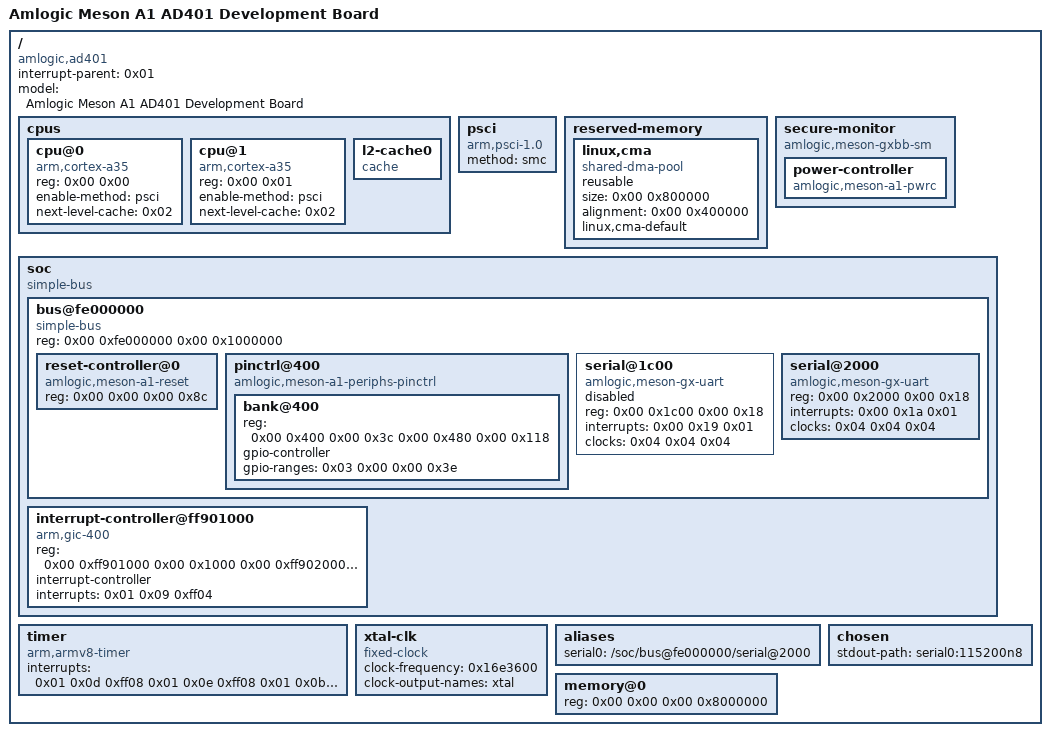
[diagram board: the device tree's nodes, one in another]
/dts-v1/;

/ {
	compatible = "amlogic,ad401\0amlogic,a1";
	interrupt-parent = <0x01>;
	#address-cells = <0x02>;
	#size-cells = <0x02>;
	model = "Amlogic Meson A1 AD401 Development Board";

	cpus {
		#address-cells = <0x02>;
		#size-cells = <0x00>;

		cpu@0 {
			device_type = "cpu";
			compatible = "arm,cortex-a35";
			reg = <0x00 0x00>;
			enable-method = "psci";
			next-level-cache = <0x02>;
			phandle = <0x05>;
		};

		cpu@1 {
			device_type = "cpu";
			compatible = "arm,cortex-a35";
			reg = <0x00 0x01>;
			enable-method = "psci";
			next-level-cache = <0x02>;
			phandle = <0x06>;
		};

		l2-cache0 {
			compatible = "cache";
			phandle = <0x02>;
		};
	};

	psci {
		compatible = "arm,psci-1.0";
		method = "smc";
	};

	reserved-memory {
		#address-cells = <0x02>;
		#size-cells = <0x02>;
		ranges;

		linux,cma {
			compatible = "shared-dma-pool";
			reusable;
			size = <0x00 0x800000>;
			alignment = <0x00 0x400000>;
			linux,cma-default;
		};
	};

	secure-monitor {
		compatible = "amlogic,meson-gxbb-sm";
		phandle = <0x07>;

		power-controller {
			compatible = "amlogic,meson-a1-pwrc";
			#power-domain-cells = <0x01>;
			status = "okay";
			phandle = <0x08>;
		};
	};

	soc {
		compatible = "simple-bus";
		#address-cells = <0x02>;
		#size-cells = <0x02>;
		ranges;

		bus@fe000000 {
			compatible = "simple-bus";
			reg = <0x00 0xfe000000 0x00 0x1000000>;
			#address-cells = <0x02>;
			#size-cells = <0x02>;
			ranges = <0x00 0x00 0x00 0xfe000000 0x00 0x1000000>;
			phandle = <0x09>;

			reset-controller@0 {
				compatible = "amlogic,meson-a1-reset";
				reg = <0x00 0x00 0x00 0x8c>;
				#reset-cells = <0x01>;
				phandle = <0x0a>;
			};

			pinctrl@400 {
				compatible = "amlogic,meson-a1-periphs-pinctrl";
				#address-cells = <0x02>;
				#size-cells = <0x02>;
				ranges;
				phandle = <0x03>;

				bank@400 {
					reg = <0x00 0x400 0x00 0x3c 0x00 0x480 0x00 0x118>;
					reg-names = "mux\0gpio";
					gpio-controller;
					#gpio-cells = <0x02>;
					gpio-ranges = <0x03 0x00 0x00 0x3e>;
					phandle = <0x0b>;
				};
			};

			serial@1c00 {
				compatible = "amlogic,meson-gx-uart\0amlogic,meson-ao-uart";
				reg = <0x00 0x1c00 0x00 0x18>;
				interrupts = <0x00 0x19 0x01>;
				clocks = <0x04 0x04 0x04>;
				clock-names = "xtal\0pclk\0baud";
				status = "disabled";
				phandle = <0x0c>;
			};

			serial@2000 {
				compatible = "amlogic,meson-gx-uart\0amlogic,meson-ao-uart";
				reg = <0x00 0x2000 0x00 0x18>;
				interrupts = <0x00 0x1a 0x01>;
				clocks = <0x04 0x04 0x04>;
				clock-names = "xtal\0pclk\0baud";
				status = "okay";
				phandle = <0x0d>;
			};
		};

		interrupt-controller@ff901000 {
			compatible = "arm,gic-400";
			reg = <0x00 0xff901000 0x00 0x1000 0x00 0xff902000 0x00 0x2000 0x00 0xff904000 0x00 0x2000 0x00 0xff906000 0x00 0x2000>;
			interrupt-controller;
			interrupts = <0x01 0x09 0xff04>;
			#interrupt-cells = <0x03>;
			#address-cells = <0x00>;
			phandle = <0x01>;
		};
	};

	timer {
		compatible = "arm,armv8-timer";
		interrupts = <0x01 0x0d 0xff08 0x01 0x0e 0xff08 0x01 0x0b 0xff08 0x01 0x0a 0xff08>;
	};

	xtal-clk {
		compatible = "fixed-clock";
		clock-frequency = <0x16e3600>;
		clock-output-names = "xtal";
		#clock-cells = <0x00>;
		phandle = <0x04>;
	};

	aliases {
		serial0 = "/soc/bus@fe000000/serial@2000";
	};

	chosen {
		stdout-path = "serial0:115200n8";
	};

	memory@0 {
		device_type = "memory";
		reg = <0x00 0x00 0x00 0x8000000>;
	};

	__symbols__ {
		cpu0 = "/cpus/cpu@0";
		cpu1 = "/cpus/cpu@1";
		l2 = "/cpus/l2-cache0";
		sm = "/secure-monitor";
		pwrc = "/secure-monitor/power-controller";
		apb = "/soc/bus@fe000000";
		reset = "/soc/bus@fe000000/reset-controller@0";
		periphs_pinctrl = "/soc/bus@fe000000/pinctrl@400";
		gpio = "/soc/bus@fe000000/pinctrl@400/bank@400";
		uart_AO = "/soc/bus@fe000000/serial@1c00";
		uart_AO_B = "/soc/bus@fe000000/serial@2000";
		gic = "/soc/interrupt-controller@ff901000";
		xtal = "/xtal-clk";
	};
};
